# R7FA0E107 register map
Vendor: Renesas Electronics Corporation; Series: RA0; File version: 1.10.00
CPU: CM23 r1p0, little endian, no MPU, no FPU, VTOR, 2 interrupt priority bits, 64 interrupts
Registers are 16-bit, read-write, reset 0x0 unless marked. A register's access mark holds for its fields unless they carry their own. Offsets are from the block's base; [hi:lo] are bit positions; {n}, {i} and the like mark numbered series; 'fields as' and 'values as' point back to an identical list.

## SAU0 — Serial Array Unit 0
Base 0x400A2000
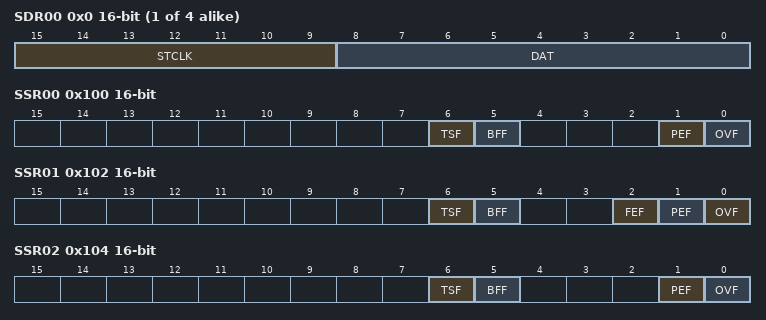
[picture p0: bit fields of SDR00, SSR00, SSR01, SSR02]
{0x0+2i} SDR0{i} (i=0..3) — Serial Data Register 0{i}
  [15:9] STCLK — Transfer Clock Setting by Dividing the Operation Clock
  [8:0] DAT — Data Buffer for Transmit and Receive
0x100 SSR00 ro — Serial Status Register 00
  [6] TSF — Flag Indicating the State of Communications for Channel n
  [5] BFF — Flag Indicating the State of the Buffer Register for Channel n
  [1] PEF — Parity or ACK Error Detection Flag of Channel n
  [0] OVF — Overrun Error Detection Flag of Channel n
0x102 SSR01 ro — Serial Status Register 01
  [6] TSF — Flag Indicating the State of Communications for Channel n
  [5] BFF — Flag Indicating the State of the Buffer Register for Channel n
  [2] FEF — Framing Error Detection Flag of Channel n
  [1] PEF — Parity or ACK Error Detection Flag of Channel n
  [0] OVF — Overrun Error Detection Flag of Channel n
0x104 SSR02 ro — Serial Status Register 02
  fields as SSR00
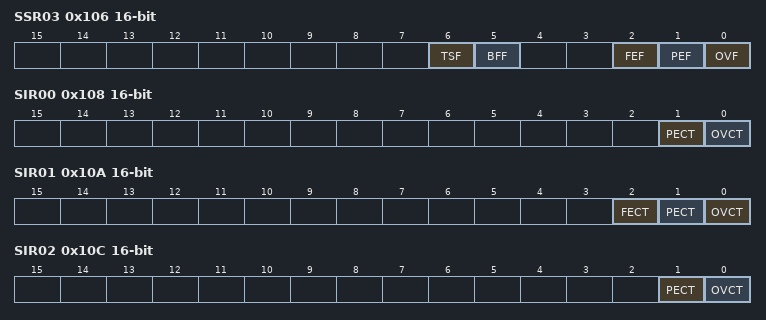
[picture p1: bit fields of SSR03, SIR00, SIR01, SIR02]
0x106 SSR03 ro — Serial Status Register 03
  fields as SSR01
0x108 SIR00 — Serial Flag Clear Trigger Register 00
  [1] PECT — Clear Trigger of Parity Error Flag of Channel n
  [0] OVCT — Clear Trigger of Overrun Error Flag of Channel n
0x10A SIR01 — Serial Flag Clear Trigger Register 01
  [2] FECT — Clear Trigger of Framing Error Flag of Channel n
  [1] PECT — Clear Trigger of Parity Error Flag of Channel n
  [0] OVCT — Clear Trigger of Overrun Error Flag of Channel n
0x10C SIR02 — Serial Flag Clear Trigger Register 02
  fields as SIR00
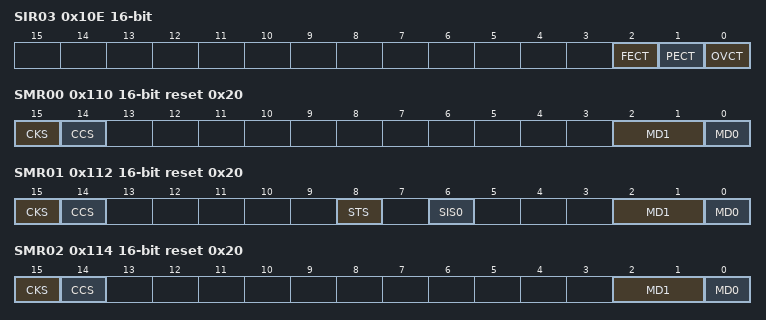
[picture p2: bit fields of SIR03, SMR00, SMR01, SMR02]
0x10E SIR03 — Serial Flag Clear Trigger Register 03
  fields as SIR01
0x110 SMR00 reset 0x20 — Serial Mode Register 00
  [15] CKS — Selection of Operation Clock (fMCK) of Channel n
  [14] CCS — Selection of Transfer Clock (fTCLK) of Channel n
  [2:1] MD1 — Setting of Channel n Operation Mode
  [0] MD0 — Selection of Channel n Interrupt Source
0x112 SMR01 reset 0x20 — Serial Mode Register 01
  [15] CKS — Selection of Operation Clock (fMCK) of Channel n
  [14] CCS — Selection of Transfer Clock (fTCLK) of Channel n
  [8] STS — Selection of Start Trigger Source
  [6] SIS0 — Controls Inversion of Level of Channel n Receive Data in UART Mode
  [2:1] MD1 — Setting of Channel n Operation Mode
  [0] MD0 — Selection of Channel n Interrupt Source
0x114 SMR02 reset 0x20 — Serial Mode Register 02
  fields as SMR00
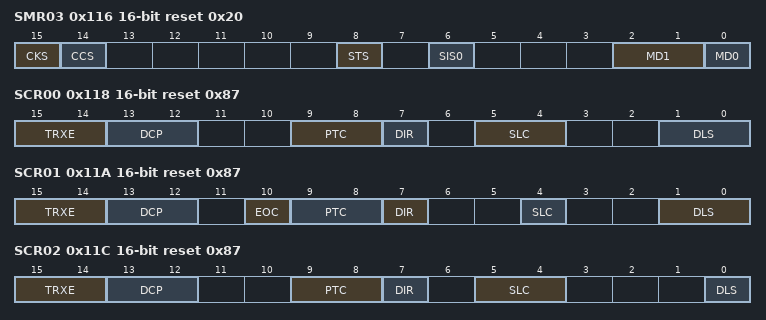
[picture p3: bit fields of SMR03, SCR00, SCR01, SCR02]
0x116 SMR03 reset 0x20 — Serial Mode Register 03
  fields as SMR01
0x118 SCR00 reset 0x87 — Serial Communication Operation Setting Register 00
  [15:14] TRXE — Setting of Channel 0 Operation Mode
  [13:12] DCP — Selection of Data and Clock Phase in Simplified SPI Mode
  [9:8] PTC — Setting of Parity Bit in UART Mode
  [7] DIR — Selection of Data Transfer Sequence in Simplified SPI and UART Modes
  [5:4] SLC — Setting of Stop Bit in UART Mode
  [1:0] DLS — Setting of Data Length in Simplified SPI and UART Modes
0x11A SCR01 reset 0x87 — Serial Communication Operation Setting Register 01
  [15:14] TRXE — Setting of Channel 1 Operation Mode
  [13:12] DCP — Selection of Data and Clock Phase in Simplified SPI Mode
  [10] EOC — Mask Control of Error Interrupt Signal SAU0_UART_ERRI0 (m = 0), SAU1_UART_ERRI2 (m = 1)
  [9:8] PTC — Setting of Parity Bit in UART Mode
  [7] DIR — Selection of Data Transfer Sequence in Simplified SPI and UART Modes
  [4] SLC — Setting of Stop Bit in UART Mode
  [1:0] DLS — Setting of Data Length in Simplified SPI and UART Modes
0x11C SCR02 reset 0x87 — Serial Communication Operation Setting Register 02
  [15:14] TRXE — Setting of Channel 2 Operation Mode
  [13:12] DCP — Selection of Data and Clock Phase in Simplified SPI Mode
  [9:8] PTC — Setting of Parity Bit in UART Mode
  [7] DIR — Selection of Data Transfer Sequence in Simplified SPI and UART Modes
  [5:4] SLC — Setting of Stop Bit in UART Mode
  [0] DLS — Setting of Data Length in Simplified SPI and UART Modes
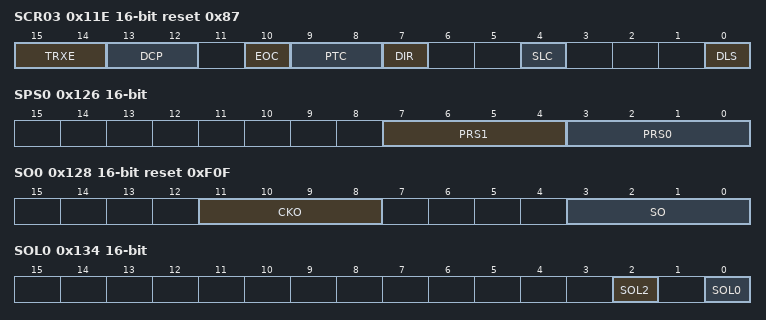
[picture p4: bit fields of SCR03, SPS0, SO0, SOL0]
0x11E SCR03 reset 0x87 — Serial Communication Operation Setting Register 03
  [15:14] TRXE — Setting of Operation Mode of Channel 3
  [13:12] DCP — Selection of Data and Clock Phase in Simplified SPI Mode
  [10] EOC — Mask Control of Error Interrupt Signal SAU0_UART_ERRI1
  [9:8] PTC — Setting of Parity Bit in UART Mode
  [7] DIR — Selection of Data Transfer Sequence in Simplified SPI and UART Modes
  [4] SLC — Setting of Stop Bit in UART Mode
  [0] DLS — Setting of Data Length in Simplified SPI and UART Modes
0x120 SE0 ro — Serial Channel Enable Status Register 0
  [3:0] SE — Indication of whether Operation of Channel n is Enabled or Stopped.
0x122 SS0 — Serial Channel Start Register 0
  [3:0] SS — Operation Start Trigger of Channel n
0x124 ST0 — Serial Channel Stop Register 0
  [3:0] ST — Operation Stop Trigger of Channel n
0x126 SPS0 — Serial Clock Select Register 0
  [7:4] PRS1 — Selection of Operation Clock (CKm1)
  [3:0] PRS0 — Selection of Operation Clock (CKm0)
0x128 SO0 reset 0xF0F — Serial Output Register 0
  [11:8] CKO — Serial Clock Output of Channel n
  [3:0] SO — Serial Data Output of Channel n
0x12A SOE0 — Serial Output Enable Register 0
  [3:0] SOE — Serial Output Enable or Stop of Channel n
0x134 SOL0 — Serial Output Level Register 0
  [2] SOL2 — Selects Inversion of the Level of the Transmit Data of Channel 2 in UART Mode
  [0] SOL0 — Selects Inversion of the Level of the Transmit Data of Channel 0 in UART Mode
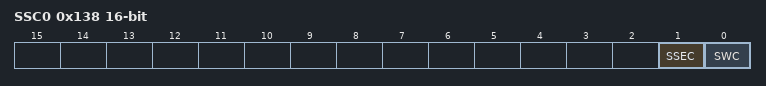
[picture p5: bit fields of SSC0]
0x138 SSC0 — Serial Standby Control Register 0
  [1] SSEC — Selection of whether to Enable or Disable the Generation of Communication Error Interrupts in the Snooze Mode
  [0] SWC — Setting of the Snooze Mode
